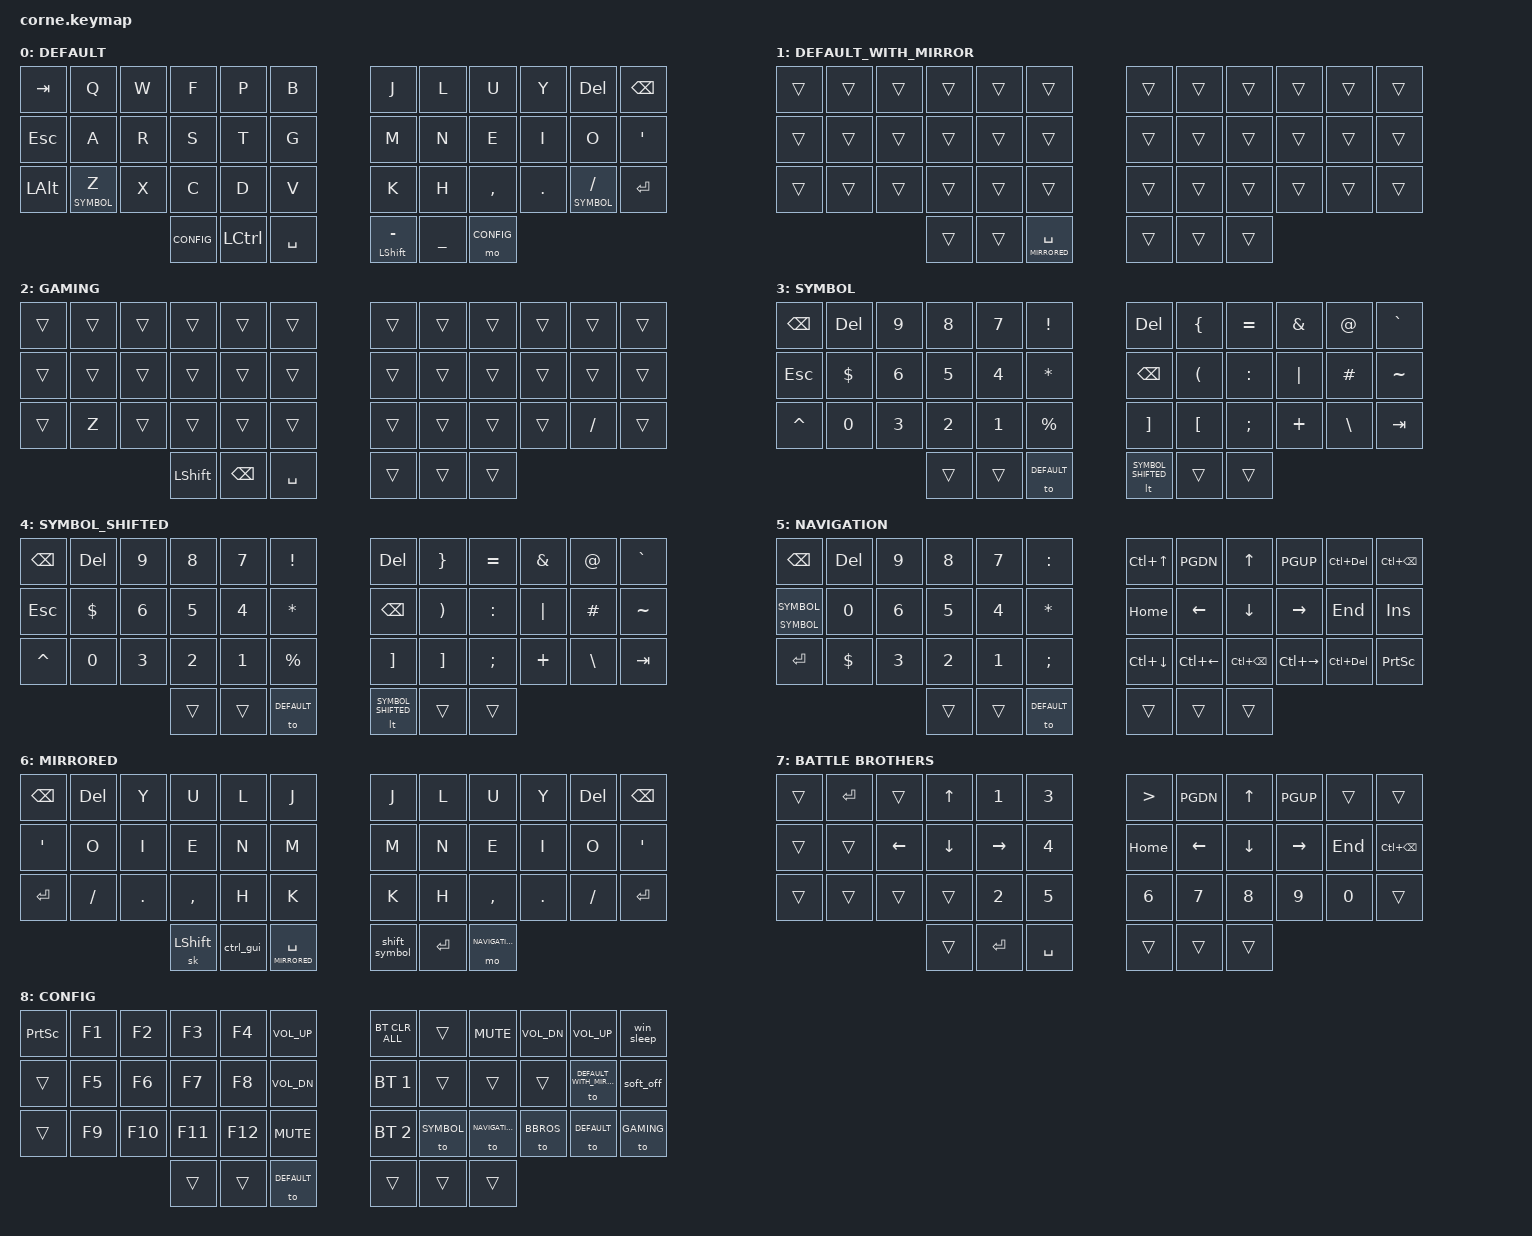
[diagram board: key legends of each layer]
/*
 * Copyright (c) 2020 The ZMK Contributors
 *
 * SPDX-License-Identifier: MIT
 */

#include <behaviors.dtsi>
#include <dt-bindings/zmk/keys.h>
#include <dt-bindings/zmk/bt.h>

#define DEFAULT 0
#define DEFAULT_WITH_MIRROR 1
#define GAMING 2
#define SYMBOL 3
#define SYMBOL_SHIFTED 4
#define NAVIGATION 5
#define MIRRORED 6
#define BBROS 7
#define CONFIG 8

#define COMBO_TIMEOUT_MS 50

/* Copied (modified) from https://github.com/caksoylar/zmk-config */
#define NAMED_COMBO(NAME, BINDINGS, KEYPOS) \
  combo_##NAME { \
    timeout-ms = <COMBO_TIMEOUT_MS>; \
    bindings = <BINDINGS>; \
    key-positions = <KEYPOS>; \
    layers = <DEFAULT DEFAULT_WITH_MIRROR MIRRORED SYMBOL NAVIGATION>; \
    slow-release; \
    require-prior-idle-ms = <125>; \
  };


// See https://stackoverflow.com/a/71899854 on why these multiple functions are necessary
// Can test output by putting these macros in a file test.c, then running 
// `gcc -E test.c`
#define NAMED_COMBO2(NAME, BINDINGS, KEYPOS) NAMED_COMBO(NAME, BINDINGS, KEYPOS)
// __LINE__ is the line number in the file, used here for uniqueness.
#define COMBO(BINDINGS, KEYPOS) NAMED_COMBO2(__LINE__, BINDINGS, KEYPOS)

/ {

macros {
     // Windows sleep key
     win_sleep: win_sleep {
         wait-ms = <500>;
         tap-ms = <5>;
         compatible = "zmk,behavior-macro";
         label = "WIN_SLEEP_KEY";
         #binding-cells = <0>;
         bindings = <&kp LG(X) &kp U &kp S>;
     };
};
behaviors {
    // These behaviors work like this:
    //  - Press once for sticky key functionality
    //  - Press and hold for holding functionality
    lmhst: layer_momentary_hold_sticky_tap {
        compatible = "zmk,behavior-hold-tap";
        #binding-cells = <2>;
        flavor = "hold-preferred";
        tapping-term-ms = <200>;
        hold-while-undecided-linger;
        retro-tap;
        bindings = <&mo>, <&sl>;
    };
    kmhst: key_momentary_hold_sticky_tap {
        compatible = "zmk,behavior-hold-tap";
        #binding-cells = <2>;
        flavor = "hold-preferred";
        tapping-term-ms = <200>;
        hold-while-undecided-linger;
        retro-tap;
        bindings = <&kp>, <&sk>;
    };
    ht_bal: balanced_hold_tap {
        compatible = "zmk,behavior-hold-tap";
        #binding-cells = <2>;
        flavor = "balanced";
        tapping-term-ms = <200>;
        retro-tap;
        bindings = <&kp>, <&kp>;
    };
    lht_bal: balanced_hold_tap_for_layers {
        compatible = "zmk,behavior-hold-tap";
        #binding-cells = <2>;
        flavor = "balanced";
        tapping-term-ms = <200>;
        retro-tap;
        bindings = <&mo>, <&kp>;
    };
    // Tap dances
    ctrl_gui: ctrl_gui_control {
        compatible = "zmk,behavior-tap-dance";
        #binding-cells = <0>;
        tapping-term-ms = <200>;
        bindings = <&kp LCTRL>, <&kp LGUI>;
    };
    shift_symbol: shift_symbol_control {
        compatible = "zmk,behavior-tap-dance";
        #binding-cells = <0>;
        tapping-term-ms = <200>;
        bindings = <&kp LSHFT>, <&mo SYMBOL>;
    };
};
combos {
    compatible = "zmk,combos";
    /*
      KEY POSITIONS
      ╭────────────────────────╮  ╭────────────────────────╮
      │ 0   1   2   3   4   5  │  │ 6   7   8   9   10  11 │
      │ 12  13  14  15  16  17 │  │ 18  19  20  21  22  23 │
      │ 24  25  26  27  28  29 │  │ 30  31  32  33  34  35 │
      ╰───────────╮ 36  37  38 │  │ 39  40  41 ╭───────────╯
                  ╰────────────╯  ╰────────────╯
    */

    // Note that these macros can be very fragile - for instance, putting
    // comments after them on the same line can break them!

    combo_symbol {
      timeout-ms = <300>;
      bindings = <&lmhst SYMBOL SYMBOL>;
      key-positions = <38 39>;
      layers = <DEFAULT DEFAULT_WITH_MIRROR MIRRORED SYMBOL NAVIGATION>;
    };

    // "Home row mods"
    // Left
    COMBO(&lmhst NAVIGATION NAVIGATION, 3 4)
    COMBO(&to NAVIGATION, 2 4)
    COMBO(&lmhst SYMBOL SYMBOL, 15 16)
    COMBO(&to SYMBOL, 14 16)
    COMBO(&kmhst LGUI LGUI, 27 28)
    COMBO(&kt LGUI, 26 28)

    // Right
    COMBO(&lmhst NAVIGATION NAVIGATION, 7 8)
    COMBO(&to NAVIGATION, 7 9)
    COMBO(&lmhst SYMBOL SYMBOL, 19 20)
    COMBO(&to SYMBOL, 19 21)
    COMBO(&kmhst LGUI LGUI, 31 32)
    COMBO(&kt LGUI, 31 33)

    // Navigation
    /*
    COMBO(&kp UP, 7 8)
    COMBO(&kp PGUP, 7 9)
    COMBO(&kp DOWN, 31 32)
    COMBO(&kp PGDN, 31 33)
    COMBO(&kp LEFT, 18 19)
    COMBO(&kp RIGHT, 20 21)
    COMBO(&kp HOME, 18 20)
    COMBO(&kp END, 20 22)
    */
};
keymap {
    compatible = "zmk,keymap";

    default_layer {
        label = "DEFAULT";
// -----------------------------------------------------------------------------------------
// | TAB  |  Q  |  W  |  F  |  P  |  B  |   |  J  |  L  |  U  |  Y  | DEL | BSPC |
// | ESC  |  A  |  R  |  S  |  T  |  G  |   |  M  |  N  |  E  |  I  |  O  |  '   |
// | ALT  |  Z  |  X  |  C  |  D  |  V  |   |  K  |  H  |  ,  |  .  |  /  | ENT  |
//                    | CONF| CTRL| SPC |   | SHF | UNDS| CONF|
        bindings = <
    &kp TAB   &kp Q             &kp W &kp F &kp P &kp B    &kp J &kp L &kp U     &kp Y   &kp DEL              &kp BSPC
    &kp ESC   &kp A             &kp R &kp S &kp T &kp G    &kp M &kp N &kp E     &kp I   &kp O                &kp SQT
    &kp LALT  &lht_bal SYMBOL Z &kp X &kp C &kp D &kp V    &kp K &kp H &kp COMMA &kp DOT &lht_bal SYMBOL FSLH &kp RET
                         &kp CONFIG &kp LCTRL &kp SPACE     &mt LSHFT MINUS &kp UNDER &mo CONFIG
        >;
    };

    default_layer_with_mirror {
        label = "DEFAULT_WITH_MIRROR";
        bindings = <
    &trans &trans &trans &trans &trans &trans       &trans &trans &trans &trans &trans &trans
    &trans &trans &trans &trans &trans &trans       &trans &trans &trans &trans &trans &trans
    &trans &trans &trans &trans &trans &trans       &trans &trans &trans &trans &trans &trans
                   &trans &trans &lt MIRRORED SPACE &trans &trans &trans
        >;
    };

    default_no_combos_layer {
        label = "GAMING";
        bindings = <
    &trans &trans &trans &trans &trans &trans &trans &trans &trans &trans &trans   &trans
    &trans &trans &trans &trans &trans &trans &trans &trans &trans &trans &trans   &trans
    &trans &kp Z  &trans &trans &trans &trans &trans &trans &trans &trans &kp FSLH &trans
                   &kp LSHFT &kp BSPC &kp SPACE &trans &trans &trans
        >;
    };

    symbol_layer {
        label = "SYMBOL";
// ----------------------------------------------------------------------------------
// |BSPC |DEL  | 9   | 8   |  7  |  !  |                    | DEL |  {  |  =  |  &  |  @  |  `   |
// | ESC | $   | 6   | 5   |  4  |  *  |                    | BSPC|  (  |  :  |  |  |  #  |  ~   |
// | ^   | 0   | 3   | 2   |  1  |  %  |                    |  +  |  [  |  ;  | Ent |  \  |  Tab |
//                   |     |     | DEF |                    |     |     |     |
        bindings = <
    &kp BSPC  &kp DEL  &kp N9 &kp N8 &kp N7 &kp EXCL    &kp DEL  &kp LBRC &kp EQUAL &kp AMPS &kp AT   &kp GRAVE
    &kp ESC   &kp DLLR &kp N6 &kp N5 &kp N4 &kp ASTRK   &kp BSPC &kp LPAR &kp COLON &kp PIPE &kp HASH &kp TILDE
    &kp CARET &kp N0   &kp N3 &kp N2 &kp N1 &kp PRCNT   &kp RBKT &kp LBKT &kp SEMI  &kp PLUS &kp BSLH &kp TAB
                         &trans &trans &to DEFAULT          &lt SYMBOL_SHIFTED &trans  &trans
        >;
    };

    symbol_shifted_layer {
        label = "SYMBOL_SHIFTED";
// ----------------------------------------------------------------------------------
// |BSPC |DEL  | 9   | 8   |  7  |  !  |                    | DEL |   } |  =  |  &  |  @  |  `   |
// | ESC | $   | 6   | 5   |  4  |  *  |                    | BSPC|   ) |  :  |  |  |  #  |  ~   |
// | ^   | 0   | 3   | 2   |  1  |  %  |                    |  +  |   ] |  ;  | Ent |  \  |  Tab |
//                   |     |     | DEF |                    |     |     |     |
        bindings = <
    &kp BSPC  &kp DEL  &kp N9 &kp N8 &kp N7 &kp EXCL    &kp DEL  &kp RBRC &kp EQUAL &kp AMPS &kp AT   &kp GRAVE
    &kp ESC   &kp DLLR &kp N6 &kp N5 &kp N4 &kp ASTRK   &kp BSPC &kp RPAR &kp COLON &kp PIPE &kp HASH &kp TILDE
    &kp CARET &kp N0   &kp N3 &kp N2 &kp N1 &kp PRCNT   &kp RBKT &kp RBKT &kp SEMI  &kp PLUS &kp BSLH &kp TAB
                         &trans &trans &to DEFAULT          &lt SYMBOL_SHIFTED &trans  &trans
        >;
    };

    navi_layer {
        label = "NAVIGATION";
// -------------------------------------------------------------------------
// |BSPC |DEL | 9   | 8   |  7  |  :  |                  |C+UP  |  PGDN |  UP  | PGUP  |C+DEL |C+BSPC|
// | SYMB| 0  | 6   | 5   |  4  |  *  |                  | HOME |  LEFT | DOWN | RIGHT |  END |INSERT|
// | ENT | $  | 3   | 2   |  1  | ;   |                  |C+DOWN| C+LEFT|C+BSPC|C+RIGHT|C+DEL |PSCRN |
//                  |     |     | DEF |                  |      |       |      |
        bindings = <
    &kp BSPC              &kp DEL  &kp N9 &kp N8 &kp N7 &kp COLON     &kp LC(UP)   &kp PGDN     &kp UP       &kp PGUP      &kp LC(DEL) &kp LC(BSPC)
    &lmhst SYMBOL SYMBOL  &kp N0   &kp N6 &kp N5 &kp N4 &kp ASTRK     &kp HOME     &kp LEFT     &kp DOWN     &kp RIGHT     &kp END     &kp INSERT
    &kp RET               &kp DLLR &kp N3 &kp N2 &kp N1 &kp SEMI      &kp LC(DOWN) &kp LC(LEFT) &kp LC(BSPC) &kp LC(RIGHT) &kp LC(DEL) &kp PSCRN
                                     &trans   &trans  &to DEFAULT           &trans     &trans   &trans
        >;
    };

    mirrored_layer {
        label = "MIRRORED";
// -----------------------------------------------------------------------------------------
// | BSPC |  DEL|  Y  |  U  |  L  |  J  |   |  J  |  L  |  U  |  Y  | DEL | BSPC |
// |  '   |  O  |  I  |  E  |  N  |  M  |   |  M  |  N  |  E  |  I  |  O  |  '   |
// | ENT  |  /  |  .  |  ,  |  H  |  K  |   |  K  |  H  |  ,  |  .  |  /  | ENT  |
//                    | SHFT| CTRL| SPC |   | SHF | ENT | NAVI|
        bindings = <
    &kp BSPC &kp DEL  &kp Y   &kp U     &kp L &kp J   &kp J &kp L &kp U     &kp Y   &kp DEL  &kp BSPC
    &kp SQT  &kp O    &kp I   &kp E     &kp N &kp M   &kp M &kp N &kp E     &kp I   &kp O    &kp SQT
    &kp RET  &kp FSLH &kp DOT &kp COMMA &kp H &kp K   &kp K &kp H &kp COMMA &kp DOT &kp FSLH &kp RET
             &sk LSHFT &ctrl_gui &mt MIRRORED SPACE   &shift_symbol &kp RET &mo NAVIGATION
        >;
    };

    bbros_layer {
        label = "BATTLE BROTHERS";
// -------------------------------------------------------------------------
// |     |ENT |     | UP   | 1   |  3   |                  | >    |  PGDN |  UP  | PGUP  |      |       |
// |     |    | LEFT| DOWN |RIGHT|  4   |                  | HOME |  LEFT | DOWN | RIGHT |  END |C+BSPC |
// |     |    |     |      |  2  |  5   |                  | 6    |  7    |   8  |   9   |   0  |       |
//                  |      | ENT | SPC  |                  |      |       |      |
        bindings = <
    &trans    &kp RET &trans   &kp UP    &kp N1    &kp N3       &kp GT     &kp PGDN &kp UP   &kp PGUP  &trans   &trans
    &trans    &trans  &kp LEFT &kp DOWN  &kp RIGHT &kp N4       &kp HOME   &kp LEFT &kp DOWN &kp RIGHT &kp END  &kp LC(BSPC)
    &trans    &trans  &trans   &trans    &kp N2    &kp N5       &kp N6     &kp N7   &kp N8   &kp N9    &kp N0   &trans
                            &trans   &kp RET    &kp SPACE       &trans     &trans   &trans
        >;
    };

    config_layer {
        label = "CONFIG";
// -------------------------------------------------------------------------
// | PSCRN | F1 | F2  | F3  | F4  | VOL+ |                  | BTCAL|       | MUTE  | VOL- | VOL+ | SLEEP    |
// |       | F5 | F6  | F7  | F8  | VOL- |                  | BT1  |       |       |      |MIRROR| OFF      |
// |       | F9 | F10 | F11 | F12 | MUTE |                  | BT2  |  SYMB | NAVI  |BBROS |DEFAUL| NO_COMBO |
//                    |     |     |      |                  |      |      |      |
        bindings = <
    &kp PSCRN &kp F1 &kp F2  &kp F3  &kp F4  &kp C_VOL_UP   &bt BT_CLR_ALL &trans      &kp C_MUTE     &kp C_VOL_DN &kp C_VOL_UP             &win_sleep
    &trans    &kp F5 &kp F6  &kp F7  &kp F8  &kp C_VOL_DN   &bt BT_SEL 1   &trans      &trans         &trans       &to DEFAULT_WITH_MIRROR  &soft_off
    &trans    &kp F9 &kp F10 &kp F11 &kp F12 &kp C_MUTE     &bt BT_SEL 2   &to SYMBOL  &to NAVIGATION &to BBROS    &to DEFAULT              &to GAMING
                             &trans  &trans  &to DEFAULT    &trans         &trans      &trans
        >;
    };
};
};
